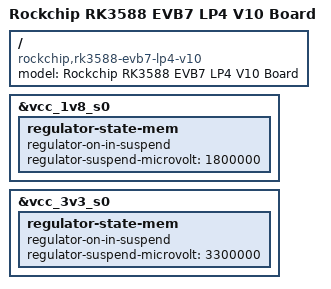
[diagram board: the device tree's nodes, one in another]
// SPDX-License-Identifier: (GPL-2.0+ OR MIT)
/*
 * Copyright (c) 2022 Rockchip Electronics Co., Ltd.
 *
 */

/dts-v1/;

//#include "rk3588-evb7-lp4.dtsi"
#include "ztl-coremainboard-v01.dtsi"
//#include "ztl-a588-v01.dtsi"
//#include "rk3588-evb7-imx415.dtsi"
#include "rk3588-linux.dtsi"



/ {
	model = "Rockchip RK3588 EVB7 LP4 V10 Board";
	compatible = "rockchip,rk3588-evb7-lp4-v10", "rockchip,rk3588";



};

/*
&vcc_1v8_s0{
        regulator-always-on;
    regulator-boot-on;
    regulator-min-microvolt = <1800000>;
    regulator-max-microvolt = <1800000>;
    regulator-name = "vcc_1v8_s0";
    regulator-state-mem {
     regulator-off-in-suspend;
     regulator-suspend-microvolt = <1800000>;
	};
};

*/



&vcc_1v8_s0 {
        /delete-property/ regulator-state-mem;
        regulator-state-mem {
                regulator-on-in-suspend;
                regulator-suspend-microvolt = <1800000>;
        };
};


&vcc_3v3_s0 {
        /delete-property/ regulator-state-mem;
        regulator-state-mem {
                regulator-on-in-suspend;
                regulator-suspend-microvolt = <3300000>;
        };
};
